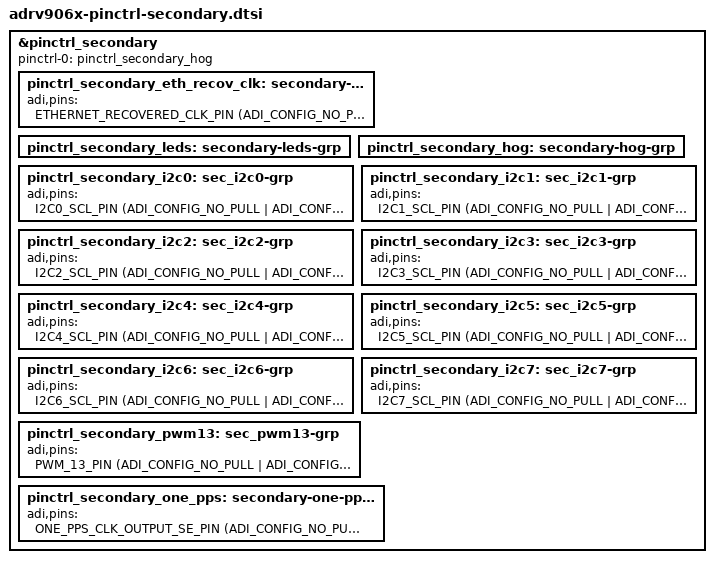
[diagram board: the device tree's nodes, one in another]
// SPDX-License-Identifier: GPL-2.0
/*
 * Copyright (c) 2024, Analog Devices Incorporated, All Rights Reserved
 */

#include <dt-bindings/pinctrl/pinctrl-adi-adrv906x-io-pad.h>
#include "adrv906x_def.h"

&pinctrl_secondary {
	pinctrl-names = "default";
	pinctrl-0 = <&pinctrl_secondary_hog>;

	pinctrl_secondary_eth_recov_clk: secondary-eth-recov-clk-grp {
		adi,pins = <
		ETHERNET_RECOVERED_CLK_PIN (ADI_CONFIG_NO_PULL | ADI_CONFIG_DRIVE_STRENGTH_4)
		>;
	};

	pinctrl_secondary_leds: secondary-leds-grp {
	};

	pinctrl_secondary_hog: secondary-hog-grp {
	};

	pinctrl_secondary_i2c0: sec_i2c0-grp {
		adi,pins = <
		I2C0_SCL_PIN	(ADI_CONFIG_NO_PULL  | ADI_CONFIG_DRIVE_STRENGTH_4)	/* DedicatedIO */
		I2C0_SDA_PIN	(ADI_CONFIG_NO_PULL  | ADI_CONFIG_DRIVE_STRENGTH_4)	/* DedicatedIO */
		>;
	};

	pinctrl_secondary_i2c1: sec_i2c1-grp {
		adi,pins = <
		I2C1_SCL_PIN	(ADI_CONFIG_NO_PULL  | ADI_CONFIG_DRIVE_STRENGTH_4)
		I2C1_SDA_PIN	(ADI_CONFIG_NO_PULL  | ADI_CONFIG_DRIVE_STRENGTH_4)
		>;
	};

	pinctrl_secondary_i2c2: sec_i2c2-grp {
		adi,pins = <
		I2C2_SCL_PIN	(ADI_CONFIG_NO_PULL  | ADI_CONFIG_DRIVE_STRENGTH_4)
		I2C2_SDA_PIN	(ADI_CONFIG_NO_PULL  | ADI_CONFIG_DRIVE_STRENGTH_4)
		>;
	};

	pinctrl_secondary_i2c3: sec_i2c3-grp {
		adi,pins = <
		I2C3_SCL_PIN	(ADI_CONFIG_NO_PULL  | ADI_CONFIG_DRIVE_STRENGTH_4)
		I2C3_SDA_PIN	(ADI_CONFIG_NO_PULL  | ADI_CONFIG_DRIVE_STRENGTH_4)
		>;
	};

	pinctrl_secondary_i2c4: sec_i2c4-grp {
		adi,pins = <
		I2C4_SCL_PIN	(ADI_CONFIG_NO_PULL  | ADI_CONFIG_DRIVE_STRENGTH_4)
		I2C4_SDA_PIN	(ADI_CONFIG_NO_PULL  | ADI_CONFIG_DRIVE_STRENGTH_4)
		>;
	};

	pinctrl_secondary_i2c5: sec_i2c5-grp {
		adi,pins = <
		I2C5_SCL_PIN	(ADI_CONFIG_NO_PULL  | ADI_CONFIG_DRIVE_STRENGTH_4)
		I2C5_SDA_PIN	(ADI_CONFIG_NO_PULL  | ADI_CONFIG_DRIVE_STRENGTH_4)
		>;
	};

	pinctrl_secondary_i2c6: sec_i2c6-grp {
		adi,pins = <
		I2C6_SCL_PIN	(ADI_CONFIG_NO_PULL  | ADI_CONFIG_DRIVE_STRENGTH_4)
		I2C6_SDA_PIN	(ADI_CONFIG_NO_PULL  | ADI_CONFIG_DRIVE_STRENGTH_4)
		>;
	};

	pinctrl_secondary_i2c7: sec_i2c7-grp {
		adi,pins = <
		I2C7_SCL_PIN	(ADI_CONFIG_NO_PULL  | ADI_CONFIG_DRIVE_STRENGTH_4)
		I2C7_SDA_PIN	(ADI_CONFIG_NO_PULL  | ADI_CONFIG_DRIVE_STRENGTH_4)
		>;
	};

	pinctrl_secondary_pwm13: sec_pwm13-grp {
		adi,pins = <
		PWM_13_PIN		(ADI_CONFIG_NO_PULL  | ADI_CONFIG_DRIVE_STRENGTH_4)
		>;
	};

	pinctrl_secondary_one_pps: secondary-one-pps-grp {
		adi,pins = <
		ONE_PPS_CLK_OUTPUT_SE_PIN	(ADI_CONFIG_NO_PULL  | ADI_CONFIG_DRIVE_STRENGTH_4)
		>;
	};
};
